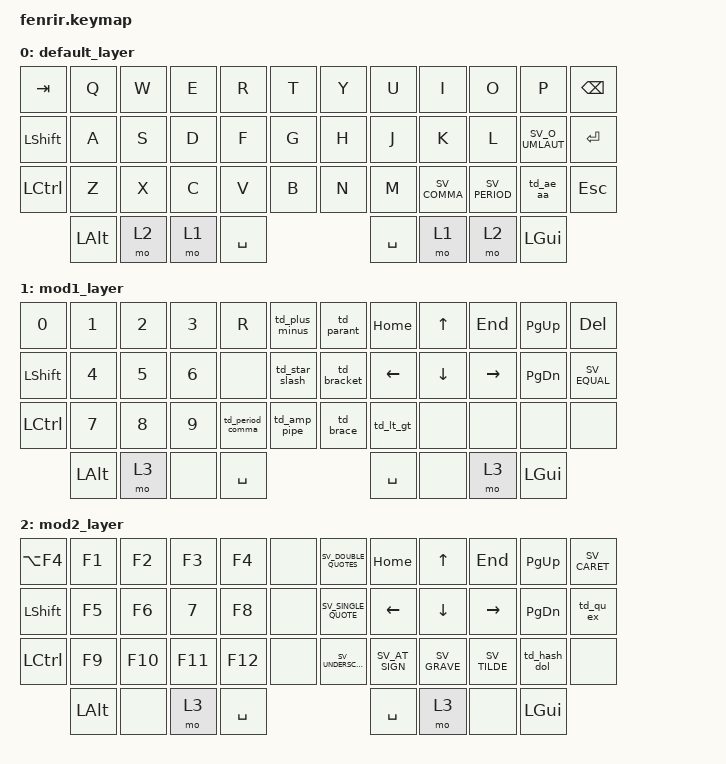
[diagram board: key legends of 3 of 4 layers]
#include <behaviors.dtsi>
#include <dt-bindings/zmk/keys.h>
#include <dt-bindings/zmk/bt.h>
#include "keys_sv.h"


#define COMBO(NAME, BINDINGS, KEYPOS, LAYER) \
  combo_##NAME { \
    timeout-ms = <50>; \
    bindings = <BINDINGS>; \
    key-positions = <KEYPOS>; \
    layers = <LAYER>; \
  };
  
/ {
    behaviors {   
        rp: require_prior_idle {
            compatible = "zmk,behavior-hold-tap";
            #binding-cells = <2>;
            flavor = "tap-preferred";
            tapping-term-ms = <300>;
            quick-tap-ms = <200>;
            require-prior-idle-ms = <200>;
            bindings = <&kp>, <&kp>;
        };

        td_plus_minus: plus_minus {
            compatible = "zmk,behavior-tap-dance";
            #binding-cells = <0>;
            tapping-term-ms = <300>;
            bindings = <&kp SV_PLUS>, <&kp SV_MINUS>;
        };

        td_star_slash: star_slash {
            compatible = "zmk,behavior-tap-dance";
            #binding-cells = <0>;
            tapping-term-ms = <300>;
            bindings = <&kp SV_STAR>, <&kp SV_SLASH>;
        };

        td_amp_pipe: amp_pipe {
            compatible = "zmk,behavior-tap-dance";
            #binding-cells = <0>;
            tapping-term-ms = <300>;
            bindings = <&kp SV_AMPERSAND>, <&kp SV_PIPE>;
        };

        td_period_comma: period_comma {
            compatible = "zmk,behavior-tap-dance";
            #binding-cells = <0>;
            tapping-term-ms = <300>;
            bindings = <&kp SV_PERIOD>, <&kp SV_COMMA>;
        };

        td_parant: parant {
            compatible = "zmk,behavior-tap-dance";
            #binding-cells = <0>;
            tapping-term-ms = <300>;
            bindings = <&kp SV_LEFT_PARENTHESIS>, <&kp SV_RIGHT_PARENTHESIS>;
        };

        td_bracket: bracket {
            compatible = "zmk,behavior-tap-dance";
            #binding-cells = <0>;
            tapping-term-ms = <300>;
            bindings = <&kp SV_LEFT_BRACKET>, <&kp SV_RIGHT_BRACKET>;
        };

        td_brace: brace {
            compatible = "zmk,behavior-tap-dance";
            #binding-cells = <0>;
            tapping-term-ms = <300>;
            bindings = <&kp SV_LEFT_BRACE>, <&kp SV_RIGHT_BRACE>;
        };

        td_lt_gt: lt_gt {
            compatible = "zmk,behavior-tap-dance";
            #binding-cells = <0>;
            tapping-term-ms = <300>;
            bindings = <&kp SV_LESS_THAN>, <&kp SV_GREATER_THAN>;
        };

        td_qu_ex: qu_ex {
            compatible = "zmk,behavior-tap-dance";
            #binding-cells = <0>;
            tapping-term-ms = <300>;
            bindings = <&kp SV_QUESTION>, <&kp SV_EXCLAMATION>;
        };

        td_hash_dol: hash_dol {
            compatible = "zmk,behavior-tap-dance";
            #binding-cells = <0>;
            tapping-term-ms = <300>;
            bindings = <&kp SV_HASH>, <&kp SV_DOLLAR>;
        };

        td_ae_aa: ae_aa {
            compatible = "zmk,behavior-tap-dance";
            #binding-cells = <0>;
            tapping-term-ms = <300>;
            bindings = <&kp SV_A_UMLAUT>, <&kp SV_A_RING>; 
        };

        td_1_2: lay_1_2 {
            compatible = "zmk,behavior-tap-dance";
            #binding-cells = <0>;
            tapping-term-ms = <300>;
            bindings = <&mo 1>, <&mo 2>;
            
        };
    
    };



    combos {
    compatible = "zmk,combos";
  
    //COMBO(lesc, &kp ESC, 1 2, 0)
     
    };
    
    
    keymap {
        compatible = "zmk,keymap";

        default_layer {

// -----------------------------------------------------------------------------------------
// | TAB |  Q  |  W  |  E  |  R  |  T  |            |  Y  |  U  |  I  |  O  |  P  | BKS |
// | SHF |  A  |  S  |  D  |  F  |  G  |            |  H  |  J  |  K  |  L  |  Ö  | RET |
// | CTR |  Z  |  X  |  C  |  V  |  B  |            |  N  |  M  |  ,  |  .  | Ä Å | ESC |
//       | ALT | MO2 | MO1 |SPACE|                        |SPACE| MO1 | MO2 | GUI |
    
            bindings = <
    &kp TAB     &kp Q     &kp W  &kp E  &kp R      &kp T      &kp Y  &kp U      &kp I        &kp O         &kp P            &kp BSPC
    &kp LSHIFT  &kp A     &kp S  &kp D  &kp F      &kp G      &kp H  &kp J      &kp K        &kp L         &kp SV_O_UMLAUT  &kp RET
    &kp LCTRL   &kp Z     &kp X  &kp C  &kp V      &kp B      &kp N  &kp M      &kp SV_COMMA &kp SV_PERIOD &td_ae_aa        &kp ESC
                &kp LALT  &mo 2  &mo 1  &kp SPACE                    &kp SPACE  &mo 1        &mo 2         &kp LGUI
            >;
        };

        mod1_layer {

// -----------------------------------------------------------------------------------------
// |  0  |  1  |  2  |  3  | % \ | + - |            | ( ) | HOM | uAr | END | pUp | DEL |
// | SHF |  4  |  5  |  6  |     | * / |            | [ ] | lAr | dAr | rAr | pDn |  =  |
// | CTL |  7  |  8  |  9  | . , | & | |            | { } | < > |     |     |     |     |
//       | ALT | MO3 | MOD |SPACE|                        |SPACE| MOD | MO3 | GUI |
    
            bindings = <
    &kp N0      &kp N1    &kp N2  &kp N3  &kp R             &td_plus_minus        &td_parant   &kp HOME   &kp UP    &kp END    &kp PG_UP  &kp DEL
    &kp LSHIFT  &kp N4    &kp N5  &kp N6  &none             &td_star_slash        &td_bracket  &kp LEFT   &kp DOWN  &kp RIGHT  &kp PG_DN  &kp SV_EQUAL
    &kp LCTRL   &kp N7    &kp N8  &kp N9  &td_period_comma  &td_amp_pipe          &td_brace    &td_lt_gt  &none     &none      &none      &none
                &kp LALT  &mo 3   &none   &kp SPACE                                            &kp SPACE  &none     &mo 3      &kp LGUI
            >;
        };

        mod2_layer {

// -----------------------------------------------------------------------------------------
// | OFF |  F1 |  F2 |  F3 |  F4 |     |            |  "  | HOM | uAr | END | pUp |  ^  |
// | SHF |  F5 |  F6 |  F7 |  F8 |     |            |  '  | lAr | dAr | rAr | pDn | ? ! |
// | CTL |  F9 | F10 | F11 | F12 |     |            |  _  |  @  |  `  |  ~  | # $ |     |
//       | ALT | MOD | MO3 |SPACE|                        |SPACE| MO3 | MOD | GUI |
    
            bindings = <
    &kp LA(F4)  &kp F1    &kp F2   &kp F3   &kp F4     &none        &kp SV_DOUBLE_QUOTES  &kp HOME        &kp UP        &kp END       &kp PG_UP     &kp SV_CARET
    &kp LSHIFT  &kp F5    &kp F6   &kp N7   &kp F8     &none        &kp SV_SINGLE_QUOTE   &kp LEFT        &kp DOWN      &kp RIGHT     &kp PG_DN     &td_qu_ex
    &kp LCTRL   &kp F9    &kp F10  &kp F11  &kp F12    &none        &kp SV_UNDERSCORE     &kp SV_AT_SIGN  &kp SV_GRAVE  &kp SV_TILDE  &td_hash_dol  &none
                &kp LALT  &none    &mo 3    &kp SPACE                                     &kp SPACE       &mo 3         &none         &kp LGUI
            >;
        };

        mod3_layer {

// -----------------------------------------------------------------------------------------
// |     |     |     |     |     |     |            |     |     |     |     |     |     |
// | SHF |     |     |     |     |     |            |     |     |     |     |     |     |
// | CTL |     |     |     |     |     |            |     |     |     |     |     |     |
//       | ALT | MOD | MO3 |SPACE|                        |SPACE| MO3 | MOD | GUI |
    
            bindings = <
    &none  &none     &none  &none  &none      &none       &none  &none      &none  &none  &none     &none
    &none  &none     &none  &none  &none      &none       &none  &none      &none  &none  &none     &none
           &kp LALT  &none  &none  &kp SPACE                     &kp SPACE  &none  &none  &kp LGUI
            >;
        };

    };
};
